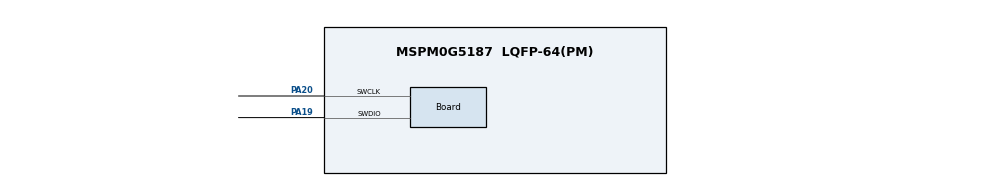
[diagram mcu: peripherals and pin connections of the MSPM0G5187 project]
//@cliArgs --device "MSPM0G518X" --package "LQFP-64(PM)" --part "Default"
//@v2CliArgs --device "MSPM0G5187" --package "LQFP-64(PM)"
// @cliArgs --board /ti/boards/LP_MSPM0G5187 --rtos nortos

/**
 * Import the modules used in this configuration.
 */
const Board    = scripting.addModule("/ti/driverlib/Board");
const CAPTURE  = scripting.addModule("/ti/driverlib/CAPTURE", {}, false);
const CAPTURE1 = CAPTURE.addInstance();
const COMP     = scripting.addModule("/ti/driverlib/COMP", {}, false);
const COMP1    = COMP.addInstance();
const SYSCTL   = scripting.addModule("/ti/driverlib/SYSCTL");
const VREF     = scripting.addModule("/ti/driverlib/VREF");

/**
 * Write custom configuration values to the imported modules.
 */
Board.InitPriority8               = "/ti/driverlib/VREF";
Board.configureUnused             = true;
Board.peripheral.$assign          = "DEBUGSS";
Board.peripheral.swclkPin.$assign = "PA20";
Board.peripheral.swdioPin.$assign = "PA19";

CAPTURE1.$name              = "CAPTURE_0";
CAPTURE1.timerClkSrc        = "LFCLK";
CAPTURE1.timerClkDiv        = 2;
CAPTURE1.timerPeriod        = "2s";
CAPTURE1.captSelect         = "Trigger";
CAPTURE1.subscriberPort     = "FSUB0";
CAPTURE1.subscriberChannel  = 1;
CAPTURE1.interrupts         = ["CC0_DN","ZERO"];
CAPTURE1.peripheral.$assign = "TIMG0";

COMP1.selectOutputFilter                    = "DL_COMP_FILTER_DELAY_1200";
COMP1.compMode                              = "DL_COMP_MODE_ULP";
COMP1.hysteresis                            = "DL_COMP_HYSTERESIS_30";
COMP1.vSource                               = "DL_COMP_REF_SOURCE_VDDA_DAC";
COMP1.controlSelect                         = "DL_COMP_DAC_CONTROL_SW";
COMP1.pubChanID                             = 1;
COMP1.enabledEvents                         = ["DL_COMP_EVENT_OUTPUT_EDGE"];
COMP1.channelEnable                         = ["NEG"];
COMP1.$name                                 = "COMP";
COMP1.peripheral.$assign                    = "COMP0";
COMP1.peripheral.compPinNeg0.$assign        = "PB22";
COMP1.compPinNeg0Config.hideOutputInversion = scripting.forceWrite(false);

SYSCTL.powerPolicy           = "STOP0";
SYSCTL.forceDefaultClkConfig = true;
SYSCTL.clockTreeEn           = true;

VREF.peripheral.$assign            = "VREF";

const ProjectConfig              = scripting.addModule("/ti/project_config/ProjectConfig", {}, false);
ProjectConfig.migrationCondition = true;
